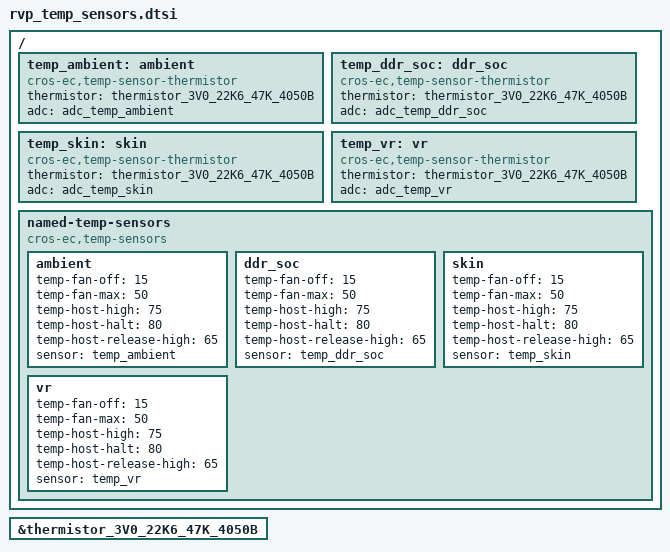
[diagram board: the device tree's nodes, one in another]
/* Copyright 2025 The ChromiumOS Authors
 * Use of this source code is governed by a BSD-style license that can be
 * found in the LICENSE file.
 */

#include <cros/thermistor/thermistor.dtsi>

/ {
	temp_ambient: ambient {
		compatible = "cros-ec,temp-sensor-thermistor";
		thermistor = <&thermistor_3V0_22K6_47K_4050B>;
		adc = <&adc_temp_ambient>;
	};

	temp_ddr_soc: ddr_soc {
		compatible = "cros-ec,temp-sensor-thermistor";
		thermistor = <&thermistor_3V0_22K6_47K_4050B>;
		adc = <&adc_temp_ddr_soc>;
	};
	temp_skin: skin {
		compatible = "cros-ec,temp-sensor-thermistor";
		thermistor = <&thermistor_3V0_22K6_47K_4050B>;
		adc = <&adc_temp_skin>;
	};
	temp_vr: vr {
		compatible = "cros-ec,temp-sensor-thermistor";
		thermistor = <&thermistor_3V0_22K6_47K_4050B>;
		adc = <&adc_temp_vr>;
	};

	named-temp-sensors {
		compatible = "cros-ec,temp-sensors";
		ambient {
			temp-fan-off = <15>;
			temp-fan-max = <50>;
			temp-host-high = <75>;
			temp-host-halt = <80>;
			temp-host-release-high = <65>;
			sensor = <&temp_ambient>;
		};

		ddr_soc {
			temp-fan-off = <15>;
			temp-fan-max = <50>;
			temp-host-high = <75>;
			temp-host-halt = <80>;
			temp-host-release-high = <65>;
			sensor = <&temp_ddr_soc>;
		};
		skin {
			temp-fan-off = <15>;
			temp-fan-max = <50>;
			temp-host-high = <75>;
			temp-host-halt = <80>;
			temp-host-release-high = <65>;
			sensor = <&temp_skin>;
		};
		vr {
			temp-fan-off = <15>;
			temp-fan-max = <50>;
			temp-host-high = <75>;
			temp-host-halt = <80>;
			temp-host-release-high = <65>;
			sensor = <&temp_vr>;
		};
	};
};

&thermistor_3V0_22K6_47K_4050B {
	status = "okay";
};
